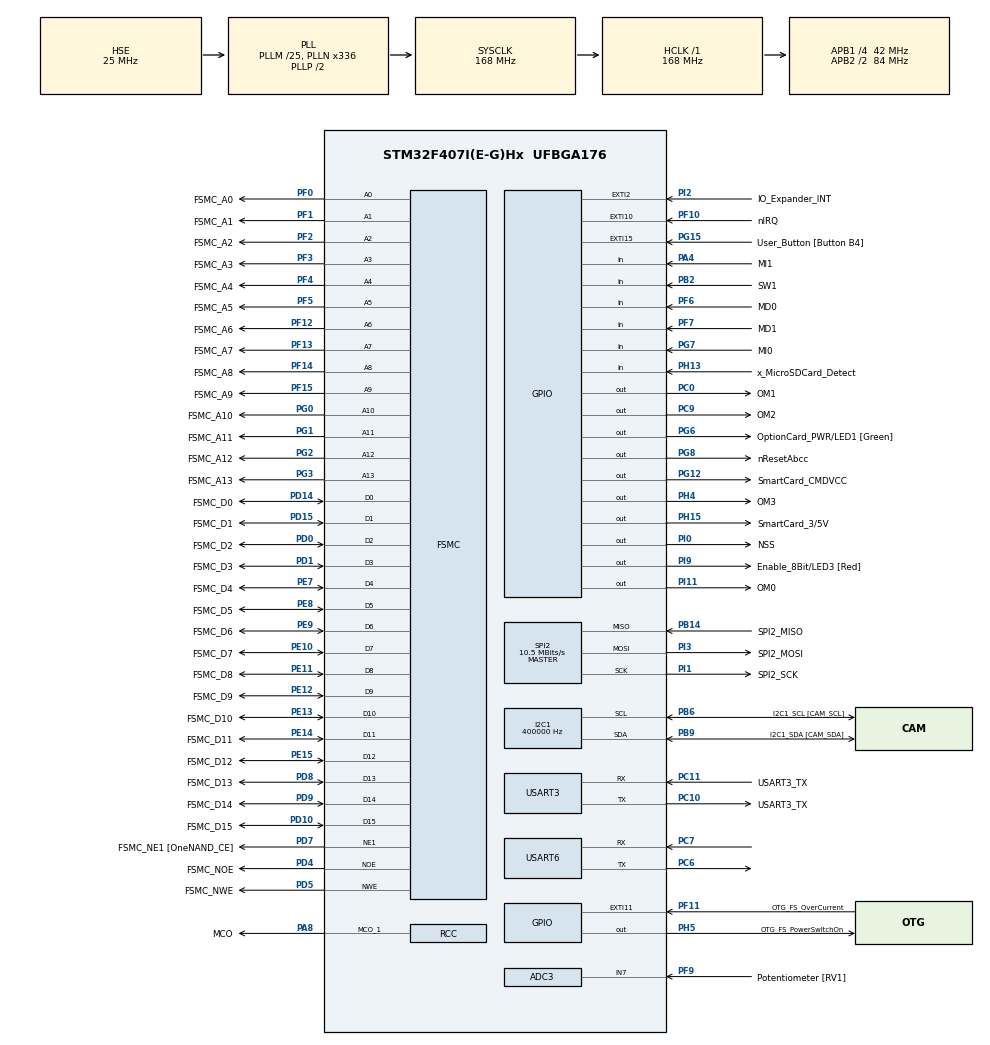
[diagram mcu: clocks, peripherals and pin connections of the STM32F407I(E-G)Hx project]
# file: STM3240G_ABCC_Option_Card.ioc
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ADC3.Channel-0\#ChannelRegularConversion=ADC_CHANNEL_7
ADC3.NbrOfConversionFlag=1
ADC3.Rank-0\#ChannelRegularConversion=1
ADC3.SamplingTime-0\#ChannelRegularConversion=ADC_SAMPLETIME_3CYCLES
Dma.Request0=SPI2_TX
Dma.Request1=SPI2_RX
Dma.SPI2_RX.1.Direction=DMA_PERIPH_TO_MEMORY
Dma.SPI2_RX.1.FIFOMode=DMA_FIFOMODE_DISABLE
Dma.SPI2_RX.1.Instance=DMA1_Stream3
Dma.SPI2_RX.1.MemDataAlignment=DMA_MDATAALIGN_BYTE
Dma.SPI2_RX.1.MemInc=DMA_MINC_ENABLE
Dma.SPI2_RX.1.Mode=DMA_NORMAL
Dma.SPI2_RX.1.PeriphDataAlignment=DMA_PDATAALIGN_BYTE
Dma.SPI2_RX.1.PeriphInc=DMA_PINC_DISABLE
Dma.SPI2_RX.1.Priority=DMA_PRIORITY_HIGH
Dma.SPI2_TX.0.Direction=DMA_MEMORY_TO_PERIPH
Dma.SPI2_TX.0.FIFOMode=DMA_FIFOMODE_DISABLE
Dma.SPI2_TX.0.Instance=DMA1_Stream4
Dma.SPI2_TX.0.MemDataAlignment=DMA_MDATAALIGN_BYTE
Dma.SPI2_TX.0.MemInc=DMA_MINC_ENABLE
Dma.SPI2_TX.0.Mode=DMA_NORMAL
Dma.SPI2_TX.0.PeriphDataAlignment=DMA_PDATAALIGN_BYTE
Dma.SPI2_TX.0.PeriphInc=DMA_PINC_DISABLE
Dma.SPI2_TX.0.Priority=DMA_PRIORITY_LOW
FSMC.AddressSetupTime1=0
FSMC.BusTurnAroundDuration1=6
FSMC.DataSetupTime1=30
I2C1.ClockSpeed=400000
I2C1.I2C_Mode=I2C_Fast
Mcu.Family=STM32F4
Mcu.Name=STM32F407I(E-G)Hx
Mcu.Package=UFBGA176
NVIC.DMA1_Stream3_IRQn=true\:0\:0\:false\:false\:true\:true
NVIC.DMA1_Stream4_IRQn=true\:0\:0\:false\:false\:true\:true
NVIC.EXTI15_10_IRQn=true\:0\:0\:false\:false\:true\:true
NVIC.PriorityGroup=NVIC_PRIORITYGROUP_0
NVIC.TIM5_IRQn=true\:0\:0\:false\:false\:true\:true
PA0-WKUP.GPIO_Label=WAKEUP [Button B2]
PA0-WKUP.Mode=SYS_WakeUp0
PA0-WKUP.Signal=SYS_WKUP
PA1.GPIO_Mode=GPIO_MODE_AF_PP
PA1.GPIO_PuPd=GPIO_NOPULL
PA1.GPIO_Speed=GPIO_SPEED_FREQ_LOW
PA1.Signal=ETH_RX_CLK
PA10.GPIO_Mode=GPIO_MODE_AF_PP
PA10.GPIO_PuPd=GPIO_NOPULL
PA10.GPIO_Speed=GPIO_SPEED_FREQ_LOW
PA10.Signal=USB_OTG_FS_ID
PA11.GPIO_Mode=GPIO_MODE_AF_PP
PA11.GPIO_PuPd=GPIO_NOPULL
PA11.GPIO_Speed=GPIO_SPEED_FREQ_LOW
PA11.Signal=USB_OTG_FS_DM
PA12.GPIO_Mode=GPIO_MODE_AF_PP
PA12.GPIO_PuPd=GPIO_NOPULL
PA12.GPIO_Speed=GPIO_SPEED_FREQ_LOW
PA12.Signal=USB_OTG_FS_DP
PA13.GPIO_Label=TMS/SWDIO
PA13.Mode=Trace_Asynchronous_SW
PA13.Signal=SYS_JTMS-SWDIO
PA14.GPIO_Label=TCK/SWCLK
PA14.Mode=Trace_Asynchronous_SW
PA14.Signal=SYS_JTCK-SWCLK
PA15.GPIO_Label=TDI
PA15.Signal=SYS_JTDI
PA2.GPIO_Mode=GPIO_MODE_AF_PP
PA2.GPIO_PuPd=GPIO_NOPULL
PA2.GPIO_Speed=GPIO_SPEED_FREQ_LOW
PA2.Signal=ETH_MDIO
PA3.GPIO_Mode=GPIO_MODE_AF_PP
PA3.GPIO_PuPd=GPIO_NOPULL
PA3.GPIO_Speed=GPIO_SPEED_FREQ_VERY_HIGH
PA3.Signal=USB_OTG_HS_ULPI_D0
PA4.GPIO_Label=MI1
PA4.GPIO_Mode=GPIO_MODE_INPUT
PA4.GPIO_PuPd=GPIO_NOPULL
PA4.Signal=GPIO_Input
PA5.GPIO_Mode=GPIO_MODE_AF_PP
PA5.GPIO_PuPd=GPIO_NOPULL
PA5.GPIO_Speed=GPIO_SPEED_FREQ_VERY_HIGH
PA5.Signal=USB_OTG_HS_ULPI_CK
PA6.GPIO_Mode=GPIO_MODE_AF_PP
PA6.GPIO_PuPd=GPIO_NOPULL
PA6.GPIO_Speed=GPIO_SPEED_FREQ_LOW
PA6.Signal=DCMI_PIXCK
PA7.GPIO_Mode=GPIO_MODE_AF_PP
PA7.GPIO_PuPd=GPIO_NOPULL
PA7.GPIO_Speed=GPIO_SPEED_FREQ_LOW
PA7.Signal=ETH_RX_DV
PA8.GPIO_Label=MCO
PA8.GPIO_Mode=GPIO_MODE_AF_PP
PA8.GPIO_PuPd=GPIO_NOPULL
PA8.GPIO_Speed=GPIO_SPEED_FREQ_LOW
PA8.Mode=Clock-out-1
PA8.Signal=RCC_MCO_1
PA9.GPIO_Mode=GPIO_MODE_INPUT
PA9.GPIO_PuPd=GPIO_NOPULL
PA9.Signal=USB_OTG_FS_VBUS
PB0.GPIO_Mode=GPIO_MODE_AF_PP
PB0.GPIO_PuPd=GPIO_NOPULL
PB0.GPIO_Speed=GPIO_SPEED_FREQ_VERY_HIGH
PB0.Signal=USB_OTG_HS_ULPI_D1
PB1.GPIO_Mode=GPIO_MODE_AF_PP
PB1.GPIO_PuPd=GPIO_NOPULL
PB1.GPIO_Speed=GPIO_SPEED_FREQ_VERY_HIGH
PB1.Signal=USB_OTG_HS_ULPI_D2
PB10.GPIO_Mode=GPIO_MODE_AF_PP
PB10.GPIO_PuPd=GPIO_NOPULL
PB10.GPIO_Speed=GPIO_SPEED_FREQ_VERY_HIGH
PB10.Signal=USB_OTG_HS_ULPI_D3
PB11.GPIO_Mode=GPIO_MODE_AF_PP
PB11.GPIO_PuPd=GPIO_NOPULL
PB11.GPIO_Speed=GPIO_SPEED_FREQ_VERY_HIGH
PB11.Signal=USB_OTG_HS_ULPI_D4
PB14.GPIO_Label=SPI2_MISO
PB14.Mode=Full_Duplex_Master
PB14.Signal=SPI2_MISO
PB2.GPIO_Label=SW1
PB2.GPIO_Mode=GPIO_MODE_INPUT
PB2.GPIO_PuPd=GPIO_NOPULL
PB2.Signal=GPIO_Input
PB3.GPIO_Label=TDO/SWO
PB3.Mode=Trace_Asynchronous_SW
PB3.Signal=SYS_JTDO-SWO
PB4.GPIO_Label=TRST
PB4.Signal=SYS_JTRST
PB5.GPIO_Mode=GPIO_MODE_AF_PP
PB5.GPIO_PuPd=GPIO_NOPULL
PB5.GPIO_Speed=GPIO_SPEED_FREQ_VERY_HIGH
PB5.Signal=USB_OTG_HS_ULPI_D7
PB6.GPIO_Label=I2C1_SCL [CAM_SCL]
PB6.GPIO_Mode=GPIO_MODE_AF_OD
PB6.GPIO_PuPd=GPIO_NOPULL
PB6.GPIO_PuPdOD=GPIO_PULLUP
PB6.GPIO_Speed=GPIO_SPEED_FREQ_LOW
PB6.Mode=I2C
PB6.Signal=I2C1_SCL
PB7.GPIO_Label=FSMC_NL [OneNAND_AVD]
PB7.GPIO_Mode=GPIO_MODE_AF_PP
PB7.GPIO_PuPd=GPIO_NOPULL
PB7.GPIO_Speed=GPIO_SPEED_FREQ_LOW
PB7.GPIO_Speed_High_Default=GPIO_SPEED_FREQ_VERY_HIGH
PB7.Signal=FSMC_NL
PB8.GPIO_Mode=GPIO_MODE_AF_PP
PB8.GPIO_PuPd=GPIO_NOPULL
PB8.GPIO_Speed=GPIO_SPEED_FREQ_LOW
PB8.Signal=ETH_TXD3
PB9.GPIO_Label=I2C1_SDA [CAM_SDA]
PB9.GPIO_Mode=GPIO_MODE_AF_OD
PB9.GPIO_PuPd=GPIO_NOPULL
PB9.GPIO_PuPdOD=GPIO_PULLUP
PB9.GPIO_Speed=GPIO_SPEED_FREQ_LOW
PB9.Mode=I2C
PB9.Signal=I2C1_SDA
PC0.GPIO_Label=OM1
PC0.GPIO_ModeDefaultOutputPP=GPIO_MODE_OUTPUT_PP
PC0.GPIO_PuPd=GPIO_PULLUP
PC0.GPIO_Speed=GPIO_SPEED_FREQ_LOW
PC0.Signal=GPIO_Output
PC1.GPIO_Mode=GPIO_MODE_AF_PP
PC1.GPIO_PuPd=GPIO_NOPULL
PC1.GPIO_Speed=GPIO_SPEED_FREQ_LOW
PC1.Signal=ETH_MDC
PC10.GPIO_Label=USART3_TX
PC10.GPIO_Mode=GPIO_MODE_AF_PP
PC10.GPIO_PuPd=GPIO_NOPULL
PC10.GPIO_Speed=GPIO_SPEED_FREQ_LOW
PC10.Mode=Asynchronous
PC10.Signal=USART3_TX
PC11.GPIO_Label=USART3_TX
PC11.GPIO_Mode=GPIO_MODE_AF_PP
PC11.GPIO_PuPd=GPIO_NOPULL
PC11.GPIO_Speed=GPIO_SPEED_FREQ_LOW
PC11.Mode=Asynchronous
PC11.Signal=USART3_RX
PC12.GPIO_Label=MicroSDCard_CLK
PC12.GPIO_Mode=GPIO_MODE_AF_PP
PC12.GPIO_PuPd=GPIO_NOPULL
PC12.GPIO_Speed=GPIO_SPEED_FREQ_LOW
PC12.GPIO_Speed_High_Default=GPIO_SPEED_FREQ_VERY_HIGH
PC12.Signal=SDIO_CK
PC13-ANTI_TAMP.GPIO_Label=Anti_Tamper [Button B3]
PC13-ANTI_TAMP.Signal=RTC_AF1
PC14-OSC32_IN.GPIO_Label=PC14-OSC32_IN
PC14-OSC32_IN.Signal=RCC_OSC32_IN
PC15-OSC32_OUT.GPIO_Label=PC15-OSC32_OUT
PC15-OSC32_OUT.Signal=RCC_OSC32_OUT
PC2.GPIO_Mode=GPIO_MODE_AF_PP
PC2.GPIO_PuPd=GPIO_NOPULL
PC2.GPIO_Speed=GPIO_SPEED_FREQ_LOW
PC2.Signal=ETH_TXD2
PC3.GPIO_Mode=GPIO_MODE_AF_PP
PC3.GPIO_PuPd=GPIO_NOPULL
PC3.GPIO_Speed=GPIO_SPEED_FREQ_LOW
PC3.Signal=ETH_TX_CLK
PC4.GPIO_Mode=GPIO_MODE_AF_PP
PC4.GPIO_PuPd=GPIO_NOPULL
PC4.GPIO_Speed=GPIO_SPEED_FREQ_LOW
PC4.Signal=ETH_RXD0
PC5.GPIO_Mode=GPIO_MODE_AF_PP
PC5.GPIO_PuPd=GPIO_NOPULL
PC5.GPIO_Speed=GPIO_SPEED_FREQ_LOW
PC5.Signal=ETH_RXD1
PC6.Mode=Asynchronous
PC6.Signal=USART6_TX
PC7.Mode=Asynchronous
PC7.Signal=USART6_RX
PC8.GPIO_Label=MicroSDCard_D0
PC8.GPIO_Mode=GPIO_MODE_AF_PP
PC8.GPIO_PuPd=GPIO_NOPULL
PC8.GPIO_Speed=GPIO_SPEED_FREQ_LOW
PC8.GPIO_Speed_High_Default=GPIO_SPEED_FREQ_VERY_HIGH
PC8.Signal=SDIO_D0
PC9.GPIO_Label=OM2
PC9.GPIO_ModeDefaultOutputPP=GPIO_MODE_OUTPUT_PP
PC9.GPIO_PuPd=GPIO_PULLUP
PC9.GPIO_Speed=GPIO_SPEED_FREQ_LOW
PC9.Signal=GPIO_Output
PD0.GPIO_Label=FSMC_D2
PD0.GPIO_Mode=GPIO_MODE_AF_PP
PD0.GPIO_PuPd=GPIO_NOPULL
PD0.GPIO_Speed=GPIO_SPEED_FREQ_LOW
PD0.GPIO_Speed_High_Default=GPIO_SPEED_FREQ_VERY_HIGH
PD0.Signal=FSMC_D2_DA2
PD1.GPIO_Label=FSMC_D3
PD1.GPIO_Mode=GPIO_MODE_AF_PP
PD1.GPIO_PuPd=GPIO_NOPULL
PD1.GPIO_Speed=GPIO_SPEED_FREQ_LOW
PD1.GPIO_Speed_High_Default=GPIO_SPEED_FREQ_VERY_HIGH
PD1.Signal=FSMC_D3_DA3
PD10.GPIO_Label=FSMC_D15
PD10.GPIO_Mode=GPIO_MODE_AF_PP
PD10.GPIO_PuPd=GPIO_NOPULL
PD10.GPIO_Speed=GPIO_SPEED_FREQ_LOW
PD10.GPIO_Speed_High_Default=GPIO_SPEED_FREQ_VERY_HIGH
PD10.Signal=FSMC_D15_DA15
PD11.GPIO_Mode=GPIO_MODE_AF_PP
PD11.GPIO_PuPd=GPIO_NOPULL
PD11.GPIO_Speed=GPIO_SPEED_FREQ_LOW
PD11.GPIO_Speed_High_Default=GPIO_SPEED_FREQ_VERY_HIGH
PD11.Signal=FSMC_A16_CLE
PD12.GPIO_Mode=GPIO_MODE_AF_PP
PD12.GPIO_PuPd=GPIO_NOPULL
PD12.GPIO_Speed=GPIO_SPEED_FREQ_LOW
PD12.GPIO_Speed_High_Default=GPIO_SPEED_FREQ_VERY_HIGH
PD12.Signal=FSMC_A17_ALE
PD13.GPIO_Mode=GPIO_MODE_AF_PP
PD13.GPIO_PuPd=GPIO_NOPULL
PD13.GPIO_Speed=GPIO_SPEED_FREQ_LOW
PD13.GPIO_Speed_High_Default=GPIO_SPEED_FREQ_VERY_HIGH
PD13.Signal=FSMC_A18
PD14.GPIO_Label=FSMC_D0
PD14.GPIO_Mode=GPIO_MODE_AF_PP
PD14.GPIO_PuPd=GPIO_NOPULL
PD14.GPIO_Speed=GPIO_SPEED_FREQ_LOW
PD14.GPIO_Speed_High_Default=GPIO_SPEED_FREQ_VERY_HIGH
PD14.Signal=FSMC_D0_DA0
PD15.GPIO_Label=FSMC_D1
PD15.GPIO_Mode=GPIO_MODE_AF_PP
PD15.GPIO_PuPd=GPIO_NOPULL
PD15.GPIO_Speed=GPIO_SPEED_FREQ_LOW
PD15.GPIO_Speed_High_Default=GPIO_SPEED_FREQ_VERY_HIGH
PD15.Signal=FSMC_D1_DA1
PD2.GPIO_Label=MicroSDCard_CMD
PD2.GPIO_Mode=GPIO_MODE_AF_PP
PD2.GPIO_PuPd=GPIO_NOPULL
PD2.GPIO_Speed=GPIO_SPEED_FREQ_LOW
PD2.GPIO_Speed_High_Default=GPIO_SPEED_FREQ_VERY_HIGH
PD2.Signal=SDIO_CMD
PD3.GPIO_Label=FSMC_CLK [OneNAND_CLK]
PD3.GPIO_Mode=GPIO_MODE_AF_PP
PD3.GPIO_PuPd=GPIO_NOPULL
PD3.GPIO_Speed=GPIO_SPEED_FREQ_LOW
PD3.GPIO_Speed_High_Default=GPIO_SPEED_FREQ_VERY_HIGH
PD3.Signal=FSMC_CLK
PD4.GPIO_Label=FSMC_NOE
PD4.GPIO_Mode=GPIO_MODE_AF_PP
PD4.GPIO_PuPd=GPIO_NOPULL
PD4.GPIO_Speed=GPIO_SPEED_FREQ_LOW
PD4.GPIO_Speed_High_Default=GPIO_SPEED_FREQ_VERY_HIGH
PD4.Signal=FSMC_NOE
PD5.GPIO_Label=FSMC_NWE
PD5.GPIO_Mode=GPIO_MODE_AF_PP
PD5.GPIO_PuPd=GPIO_NOPULL
PD5.GPIO_Speed=GPIO_SPEED_FREQ_LOW
PD5.GPIO_Speed_High_Default=GPIO_SPEED_FREQ_VERY_HIGH
PD5.Signal=FSMC_NWE
PD6.GPIO_Label=FSMC_NWAIT [OneNAND_RDY]
PD6.GPIO_Mode=GPIO_MODE_AF_PP
PD6.GPIO_PuPd=GPIO_NOPULL
PD6.GPIO_Speed=GPIO_SPEED_FREQ_LOW
PD6.GPIO_Speed_High_Default=GPIO_SPEED_FREQ_VERY_HIGH
PD6.Signal=FSMC_NWAIT
PD7.GPIO_Label=FSMC_NE1 [OneNAND_CE]
PD7.GPIO_Mode=GPIO_MODE_AF_PP
PD7.GPIO_PuPd=GPIO_NOPULL
PD7.GPIO_Speed=GPIO_SPEED_FREQ_LOW
PD7.GPIO_Speed_High_Default=GPIO_SPEED_FREQ_VERY_HIGH
PD7.Mode=NorPsramChipSelect1_1
PD7.Signal=FSMC_NE1
PD8.GPIO_Label=FSMC_D13
PD8.GPIO_Mode=GPIO_MODE_AF_PP
PD8.GPIO_PuPd=GPIO_NOPULL
PD8.GPIO_Speed=GPIO_SPEED_FREQ_LOW
PD8.GPIO_Speed_High_Default=GPIO_SPEED_FREQ_VERY_HIGH
PD8.Signal=FSMC_D13_DA13
PD9.GPIO_Label=FSMC_D14
PD9.GPIO_Mode=GPIO_MODE_AF_PP
PD9.GPIO_PuPd=GPIO_NOPULL
PD9.GPIO_Speed=GPIO_SPEED_FREQ_LOW
PD9.GPIO_Speed_High_Default=GPIO_SPEED_FREQ_VERY_HIGH
PD9.Signal=FSMC_D14_DA14
PE0.GPIO_Label=FSMC_NBL0 [SRAM_BLE]
PE0.GPIO_Mode=GPIO_MODE_AF_PP
PE0.GPIO_PuPd=GPIO_NOPULL
PE0.GPIO_Speed=GPIO_SPEED_FREQ_LOW
PE0.GPIO_Speed_High_Default=GPIO_SPEED_FREQ_VERY_HIGH
PE0.Signal=FSMC_NBL0
PE1.GPIO_Label=FSMC_NBL1 [SRAM_BHE]
PE1.GPIO_Mode=GPIO_MODE_AF_PP
PE1.GPIO_PuPd=GPIO_NOPULL
PE1.GPIO_Speed=GPIO_SPEED_FREQ_LOW
PE1.GPIO_Speed_High_Default=GPIO_SPEED_FREQ_VERY_HIGH
PE1.Signal=FSMC_NBL1
PE10.GPIO_Label=FSMC_D7
PE10.GPIO_Mode=GPIO_MODE_AF_PP
PE10.GPIO_PuPd=GPIO_NOPULL
PE10.GPIO_Speed=GPIO_SPEED_FREQ_LOW
PE10.GPIO_Speed_High_Default=GPIO_SPEED_FREQ_VERY_HIGH
PE10.Signal=FSMC_D7_DA7
PE11.GPIO_Label=FSMC_D8
PE11.GPIO_Mode=GPIO_MODE_AF_PP
PE11.GPIO_PuPd=GPIO_NOPULL
PE11.GPIO_Speed=GPIO_SPEED_FREQ_LOW
PE11.GPIO_Speed_High_Default=GPIO_SPEED_FREQ_VERY_HIGH
PE11.Signal=FSMC_D8_DA8
PE12.GPIO_Label=FSMC_D9
PE12.GPIO_Mode=GPIO_MODE_AF_PP
PE12.GPIO_PuPd=GPIO_NOPULL
PE12.GPIO_Speed=GPIO_SPEED_FREQ_LOW
PE12.GPIO_Speed_High_Default=GPIO_SPEED_FREQ_VERY_HIGH
PE12.Signal=FSMC_D9_DA9
PE13.GPIO_Label=FSMC_D10
PE13.GPIO_Mode=GPIO_MODE_AF_PP
PE13.GPIO_PuPd=GPIO_NOPULL
PE13.GPIO_Speed=GPIO_SPEED_FREQ_LOW
PE13.GPIO_Speed_High_Default=GPIO_SPEED_FREQ_VERY_HIGH
PE13.Signal=FSMC_D10_DA10
PE14.GPIO_Label=FSMC_D11
PE14.GPIO_Mode=GPIO_MODE_AF_PP
PE14.GPIO_PuPd=GPIO_NOPULL
PE14.GPIO_Speed=GPIO_SPEED_FREQ_LOW
PE14.GPIO_Speed_High_Default=GPIO_SPEED_FREQ_VERY_HIGH
PE14.Signal=FSMC_D11_DA11
PE15.GPIO_Label=FSMC_D12
PE15.GPIO_Mode=GPIO_MODE_AF_PP
PE15.GPIO_PuPd=GPIO_NOPULL
PE15.GPIO_Speed=GPIO_SPEED_FREQ_LOW
PE15.GPIO_Speed_High_Default=GPIO_SPEED_FREQ_VERY_HIGH
PE15.Signal=FSMC_D12_DA12
PE2.GPIO_Label=TRACE_CLK
PE2.GPIO_Mode=GPIO_MODE_AF_PP
PE2.GPIO_PuPd=GPIO_NOPULL
PE2.GPIO_Speed=GPIO_SPEED_FREQ_LOW
PE2.Signal=SYS_TRACECLK
PE3.GPIO_Mode=GPIO_MODE_AF_PP
PE3.GPIO_PuPd=GPIO_NOPULL
PE3.GPIO_Speed=GPIO_SPEED_FREQ_LOW
PE3.GPIO_Speed_High_Default=GPIO_SPEED_FREQ_VERY_HIGH
PE3.Signal=FSMC_A19
PE4.GPIO_Mode=GPIO_MODE_AF_PP
PE4.GPIO_PuPd=GPIO_NOPULL
PE4.GPIO_Speed=GPIO_SPEED_FREQ_LOW
PE4.GPIO_Speed_High_Default=GPIO_SPEED_FREQ_VERY_HIGH
PE4.Signal=FSMC_A20
PE5.GPIO_Label=TRACE_D2
PE5.GPIO_Mode=GPIO_MODE_AF_PP
PE5.GPIO_PuPd=GPIO_NOPULL
PE5.GPIO_Speed=GPIO_SPEED_FREQ_LOW
PE5.Signal=SYS_TRACED2
PE6.GPIO_Label=TRACE_D3
PE6.GPIO_Mode=GPIO_MODE_AF_PP
PE6.GPIO_PuPd=GPIO_NOPULL
PE6.GPIO_Speed=GPIO_SPEED_FREQ_LOW
PE6.Signal=SYS_TRACED3
PE7.GPIO_Label=FSMC_D4
PE7.GPIO_Mode=GPIO_MODE_AF_PP
PE7.GPIO_PuPd=GPIO_NOPULL
PE7.GPIO_Speed=GPIO_SPEED_FREQ_LOW
PE7.GPIO_Speed_High_Default=GPIO_SPEED_FREQ_VERY_HIGH
PE7.Signal=FSMC_D4_DA4
PE8.GPIO_Label=FSMC_D5
PE8.GPIO_Mode=GPIO_MODE_AF_PP
PE8.GPIO_PuPd=GPIO_NOPULL
PE8.GPIO_Speed=GPIO_SPEED_FREQ_LOW
PE8.GPIO_Speed_High_Default=GPIO_SPEED_FREQ_VERY_HIGH
PE8.Signal=FSMC_D5_DA5
PE9.GPIO_Label=FSMC_D6
PE9.GPIO_Mode=GPIO_MODE_AF_PP
PE9.GPIO_PuPd=GPIO_NOPULL
PE9.GPIO_Speed=GPIO_SPEED_FREQ_LOW
PE9.GPIO_Speed_High_Default=GPIO_SPEED_FREQ_VERY_HIGH
PE9.Signal=FSMC_D6_DA6
PF0.GPIO_Label=FSMC_A0
PF0.GPIO_Mode=GPIO_MODE_AF_PP
PF0.GPIO_PuPd=GPIO_NOPULL
PF0.GPIO_Speed=GPIO_SPEED_FREQ_LOW
PF0.GPIO_Speed_High_Default=GPIO_SPEED_FREQ_VERY_HIGH
PF0.Signal=FSMC_A0
PF1.GPIO_Label=FSMC_A1
PF1.GPIO_Mode=GPIO_MODE_AF_PP
PF1.GPIO_PuPd=GPIO_NOPULL
PF1.GPIO_Speed=GPIO_SPEED_FREQ_LOW
PF1.GPIO_Speed_High_Default=GPIO_SPEED_FREQ_VERY_HIGH
PF1.Signal=FSMC_A1
PF10.GPIO_Label=nIRQ
PF10.GPIO_ModeDefaultEXTI=GPIO_MODE_IT_FALLING
PF10.GPIO_PuPd=GPIO_PULLUP
PF10.Signal=GPXTI10
PF11.GPIO_Label=OTG_FS_OverCurrent
PF11.GPIO_ModeDefaultEXTI=GPIO_MODE_EVT_RISING
PF11.GPIO_PuPd=GPIO_NOPULL
PF11.Signal=GPXTI11
PF12.GPIO_Label=FSMC_A6
PF12.GPIO_Mode=GPIO_MODE_AF_PP
PF12.GPIO_PuPd=GPIO_NOPULL
PF12.GPIO_Speed=GPIO_SPEED_FREQ_LOW
PF12.GPIO_Speed_High_Default=GPIO_SPEED_FREQ_VERY_HIGH
PF12.Signal=FSMC_A6
PF13.GPIO_Label=FSMC_A7
PF13.GPIO_Mode=GPIO_MODE_AF_PP
PF13.GPIO_PuPd=GPIO_NOPULL
PF13.GPIO_Speed=GPIO_SPEED_FREQ_LOW
PF13.GPIO_Speed_High_Default=GPIO_SPEED_FREQ_VERY_HIGH
PF13.Signal=FSMC_A7
PF14.GPIO_Label=FSMC_A8
PF14.GPIO_Mode=GPIO_MODE_AF_PP
PF14.GPIO_PuPd=GPIO_NOPULL
PF14.GPIO_Speed=GPIO_SPEED_FREQ_LOW
PF14.GPIO_Speed_High_Default=GPIO_SPEED_FREQ_VERY_HIGH
PF14.Signal=FSMC_A8
PF15.GPIO_Label=FSMC_A9
PF15.GPIO_Mode=GPIO_MODE_AF_PP
PF15.GPIO_PuPd=GPIO_NOPULL
PF15.GPIO_Speed=GPIO_SPEED_FREQ_LOW
PF15.GPIO_Speed_High_Default=GPIO_SPEED_FREQ_VERY_HIGH
PF15.Signal=FSMC_A9
PF2.GPIO_Label=FSMC_A2
PF2.GPIO_Mode=GPIO_MODE_AF_PP
PF2.GPIO_PuPd=GPIO_NOPULL
PF2.GPIO_Speed=GPIO_SPEED_FREQ_LOW
PF2.GPIO_Speed_High_Default=GPIO_SPEED_FREQ_VERY_HIGH
PF2.Signal=FSMC_A2
PF3.GPIO_Label=FSMC_A3
PF3.GPIO_Mode=GPIO_MODE_AF_PP
PF3.GPIO_PuPd=GPIO_NOPULL
PF3.GPIO_Speed=GPIO_SPEED_FREQ_LOW
PF3.GPIO_Speed_High_Default=GPIO_SPEED_FREQ_VERY_HIGH
PF3.Signal=FSMC_A3
PF4.GPIO_Label=FSMC_A4
PF4.GPIO_Mode=GPIO_MODE_AF_PP
PF4.GPIO_PuPd=GPIO_NOPULL
PF4.GPIO_Speed=GPIO_SPEED_FREQ_LOW
PF4.GPIO_Speed_High_Default=GPIO_SPEED_FREQ_VERY_HIGH
PF4.Signal=FSMC_A4
PF5.GPIO_Label=FSMC_A5
PF5.GPIO_Mode=GPIO_MODE_AF_PP
PF5.GPIO_PuPd=GPIO_NOPULL
PF5.GPIO_Speed=GPIO_SPEED_FREQ_LOW
PF5.GPIO_Speed_High_Default=GPIO_SPEED_FREQ_VERY_HIGH
PF5.Signal=FSMC_A5
PF6.GPIO_Label=MD0
PF6.GPIO_Mode=GPIO_MODE_INPUT
PF6.GPIO_PuPd=GPIO_NOPULL
PF6.Signal=GPIO_Input
PF7.GPIO_Label=MD1
PF7.GPIO_Mode=GPIO_MODE_INPUT
PF7.GPIO_PuPd=GPIO_NOPULL
PF7.Signal=GPIO_Input
PF9.GPIO_Label=Potentiometer [RV1]
PF9.GPIO_Mode=GPIO_MODE_ANALOG
PF9.GPIO_PuPd=GPIO_NOPULL
PF9.Mode=IN7
PF9.Signal=ADC3_IN7
PG0.GPIO_Label=FSMC_A10
PG0.GPIO_Mode=GPIO_MODE_AF_PP
PG0.GPIO_PuPd=GPIO_NOPULL
PG0.GPIO_Speed=GPIO_SPEED_FREQ_LOW
PG0.GPIO_Speed_High_Default=GPIO_SPEED_FREQ_VERY_HIGH
PG0.Signal=FSMC_A10
PG1.GPIO_Label=FSMC_A11
PG1.GPIO_Mode=GPIO_MODE_AF_PP
PG1.GPIO_PuPd=GPIO_NOPULL
PG1.GPIO_Speed=GPIO_SPEED_FREQ_LOW
PG1.GPIO_Speed_High_Default=GPIO_SPEED_FREQ_VERY_HIGH
PG1.Signal=FSMC_A11
PG10.GPIO_Label=FSMC_NE3 [TFT-LCD_CS]
PG10.GPIO_Mode=GPIO_MODE_AF_PP
PG10.GPIO_PuPd=GPIO_NOPULL
PG10.GPIO_Speed=GPIO_SPEED_FREQ_LOW
PG10.GPIO_Speed_High_Default=GPIO_SPEED_FREQ_VERY_HIGH
PG10.Signal=FSMC_NE3
PG11.GPIO_Mode=GPIO_MODE_AF_PP
PG11.GPIO_PuPd=GPIO_NOPULL
PG11.GPIO_Speed=GPIO_SPEED_FREQ_LOW
PG11.Signal=ETH_TX_EN
PG12.GPIO_Label=SmartCard_CMDVCC
PG12.GPIO_Mode=GPIO_MODE_OUTPUT_PP
PG12.GPIO_ModeDefaultOutputPP=GPIO_MODE_OUTPUT_PP
PG12.GPIO_PuPd=GPIO_NOPULL
PG12.GPIO_Speed=GPIO_SPEED_FREQ_LOW
PG12.Signal=GPIO_Output
PG13.GPIO_Mode=GPIO_MODE_AF_PP
PG13.GPIO_PuPd=GPIO_NOPULL
PG13.GPIO_Speed=GPIO_SPEED_FREQ_LOW
PG13.Signal=ETH_TXD0
PG14.GPIO_Mode=GPIO_MODE_AF_PP
PG14.GPIO_PuPd=GPIO_NOPULL
PG14.GPIO_Speed=GPIO_SPEED_FREQ_LOW
PG14.Signal=ETH_TXD1
PG15.GPIO_Label=User_Button [Button B4]
PG15.GPIO_ModeDefaultEXTI=GPIO_MODE_EVT_RISING
PG15.GPIO_PuPd=GPIO_NOPULL
PG15.Signal=GPXTI15
PG2.GPIO_Label=FSMC_A12
PG2.GPIO_Mode=GPIO_MODE_AF_PP
PG2.GPIO_PuPd=GPIO_NOPULL
PG2.GPIO_Speed=GPIO_SPEED_FREQ_LOW
PG2.GPIO_Speed_High_Default=GPIO_SPEED_FREQ_VERY_HIGH
PG2.Signal=FSMC_A12
PG3.GPIO_Label=FSMC_A13
PG3.GPIO_Mode=GPIO_MODE_AF_PP
PG3.GPIO_PuPd=GPIO_NOPULL
PG3.GPIO_Speed=GPIO_SPEED_FREQ_LOW
PG3.GPIO_Speed_High_Default=GPIO_SPEED_FREQ_VERY_HIGH
PG3.Signal=FSMC_A13
PG4.GPIO_Mode=GPIO_MODE_AF_PP
PG4.GPIO_PuPd=GPIO_NOPULL
PG4.GPIO_Speed=GPIO_SPEED_FREQ_LOW
PG4.GPIO_Speed_High_Default=GPIO_SPEED_FREQ_VERY_HIGH
PG4.Signal=FSMC_A14
PG5.GPIO_Mode=GPIO_MODE_AF_PP
PG5.GPIO_PuPd=GPIO_NOPULL
PG5.GPIO_Speed=GPIO_SPEED_FREQ_LOW
PG5.GPIO_Speed_High_Default=GPIO_SPEED_FREQ_VERY_HIGH
PG5.Signal=FSMC_A15
PG6.GPIO_Label=OptionCard_PWR/LED1 [Green]
PG6.GPIO_Mode=GPIO_MODE_OUTPUT_PP
PG6.GPIO_ModeDefaultOutputPP=GPIO_MODE_OUTPUT_PP
PG6.GPIO_PuPd=GPIO_NOPULL
PG6.GPIO_Speed=GPIO_SPEED_FREQ_LOW
PG6.PinState=GPIO_PIN_SET
PG6.Signal=GPIO_Output
PG7.GPIO_Label=MI0
PG7.GPIO_Mode=GPIO_MODE_INPUT
PG7.GPIO_PuPd=GPIO_NOPULL
PG7.Signal=GPIO_Input
PG8.GPIO_Label=nResetAbcc
PG8.GPIO_ModeDefaultOutputPP=GPIO_MODE_OUTPUT_PP
PG8.GPIO_PuPd=GPIO_PULLUP
PG8.GPIO_Speed=GPIO_SPEED_FREQ_VERY_HIGH
PG8.Signal=GPIO_Output
PG9.GPIO_Label=FSMC_NE2 [SDRAM_CE]
PG9.GPIO_Mode=GPIO_MODE_AF_PP
PG9.GPIO_PuPd=GPIO_NOPULL
PG9.GPIO_Speed=GPIO_SPEED_FREQ_LOW
PG9.GPIO_Speed_High_Default=GPIO_SPEED_FREQ_VERY_HIGH
PG9.Signal=FSMC_NE2
PH0-OSC_IN.GPIO_Label=PH0-OSC_IN
PH0-OSC_IN.Mode=HSE-External-Oscillator
PH0-OSC_IN.Signal=RCC_OSC_IN
PH1-OSC_OUT.GPIO_Label=PH1-OSC_OUT
PH1-OSC_OUT.Mode=HSE-External-Oscillator
PH1-OSC_OUT.Signal=RCC_OSC_OUT
PH10.GPIO_Mode=GPIO_MODE_AF_PP
PH10.GPIO_PuPd=GPIO_NOPULL
PH10.GPIO_Speed=GPIO_SPEED_FREQ_LOW
PH10.Signal=DCMI_D1
PH11.GPIO_Mode=GPIO_MODE_AF_PP
PH11.GPIO_PuPd=GPIO_NOPULL
PH11.GPIO_Speed=GPIO_SPEED_FREQ_LOW
PH11.Signal=DCMI_D2
PH12.GPIO_Mode=GPIO_MODE_AF_PP
PH12.GPIO_PuPd=GPIO_NOPULL
PH12.GPIO_Speed=GPIO_SPEED_FREQ_LOW
PH12.Signal=DCMI_D3
PH13.GPIO_Label=x_MicroSDCard_Detect
PH13.GPIO_Mode=GPIO_MODE_INPUT
PH13.GPIO_PuPd=GPIO_PULLUP
PH13.Signal=GPIO_Input
PH14.GPIO_Mode=GPIO_MODE_AF_PP
PH14.GPIO_PuPd=GPIO_NOPULL
PH14.GPIO_Speed=GPIO_SPEED_FREQ_LOW
PH14.Signal=DCMI_D4
PH15.GPIO_Label=SmartCard_3/5V
PH15.GPIO_Mode=GPIO_MODE_OUTPUT_PP
PH15.GPIO_ModeDefaultOutputPP=GPIO_MODE_OUTPUT_PP
PH15.GPIO_PuPd=GPIO_NOPULL
PH15.GPIO_Speed=GPIO_SPEED_FREQ_LOW
PH15.Signal=GPIO_Output
PH3.GPIO_Mode=GPIO_MODE_AF_PP
PH3.GPIO_PuPd=GPIO_NOPULL
PH3.GPIO_Speed=GPIO_SPEED_FREQ_LOW
PH3.Signal=ETH_COL
PH4.GPIO_Label=OM3
PH4.Signal=GPIO_Output
PH5.GPIO_Label=OTG_FS_PowerSwitchOn
PH5.GPIO_Mode=GPIO_MODE_OUTPUT_PP
PH5.GPIO_ModeDefaultOutputPP=GPIO_MODE_OUTPUT_PP
PH5.GPIO_PuPd=GPIO_NOPULL
PH5.GPIO_Speed=GPIO_SPEED_FREQ_LOW
PH5.Signal=GPIO_Output
PH6.GPIO_Mode=GPIO_MODE_AF_PP
PH6.GPIO_PuPd=GPIO_NOPULL
PH6.GPIO_Speed=GPIO_SPEED_FREQ_LOW
PH6.Signal=ETH_RXD2
PH7.GPIO_Mode=GPIO_MODE_AF_PP
PH7.GPIO_PuPd=GPIO_NOPULL
PH7.GPIO_Speed=GPIO_SPEED_FREQ_LOW
PH7.Signal=ETH_RXD3
PH8.GPIO_Mode=GPIO_MODE_AF_PP
PH8.GPIO_PuPd=GPIO_NOPULL
PH8.GPIO_Speed=GPIO_SPEED_FREQ_LOW
PH8.Signal=DCMI_HSYNC
PH9.GPIO_Mode=GPIO_MODE_AF_PP
PH9.GPIO_PuPd=GPIO_NOPULL
PH9.GPIO_Speed=GPIO_SPEED_FREQ_LOW
PH9.Signal=DCMI_D0
PI0.GPIO_Label=NSS
PI0.GPIO_ModeDefaultOutputPP=GPIO_MODE_OUTPUT_PP
PI0.GPIO_PuPd=GPIO_PULLUP
PI0.GPIO_Speed=GPIO_SPEED_FREQ_HIGH
PI0.Signal=GPIO_Output
PI1.GPIO_Label=SPI2_SCK
PI1.Mode=Full_Duplex_Master
PI1.Signal=SPI2_SCK
PI10.GPIO_Mode=GPIO_MODE_AF_PP
PI10.GPIO_PuPd=GPIO_NOPULL
PI10.GPIO_Speed=GPIO_SPEED_FREQ_LOW
PI10.Signal=ETH_RX_ER
PI11.GPIO_Label=OM0
PI11.GPIO_ModeDefaultOutputPP=GPIO_MODE_OUTPUT_PP
PI11.GPIO_PuPd=GPIO_PULLUP
PI11.GPIO_Speed=GPIO_SPEED_FREQ_LOW
PI11.Signal=GPIO_Output
PI2.GPIO_Label=IO_Expander_INT
PI2.GPIO_ModeDefaultEXTI=GPIO_MODE_EVT_RISING
PI2.GPIO_PuPd=GPIO_NOPULL
PI2.Signal=GPXTI2
PI3.GPIO_Label=SPI2_MOSI
PI3.Mode=Full_Duplex_Master
PI3.Signal=SPI2_MOSI
PI4.GPIO_Mode=GPIO_MODE_AF_PP
PI4.GPIO_PuPd=GPIO_NOPULL
PI4.GPIO_Speed=GPIO_SPEED_FREQ_LOW
PI4.Signal=DCMI_D5
PI5.GPIO_Mode=GPIO_MODE_AF_PP
PI5.GPIO_PuPd=GPIO_NOPULL
PI5.GPIO_Speed=GPIO_SPEED_FREQ_LOW
PI5.Signal=DCMI_VSYNC
PI6.GPIO_Mode=GPIO_MODE_AF_PP
PI6.GPIO_PuPd=GPIO_NOPULL
PI6.GPIO_Speed=GPIO_SPEED_FREQ_LOW
PI6.Signal=DCMI_D6
PI7.GPIO_Mode=GPIO_MODE_AF_PP
PI7.GPIO_PuPd=GPIO_NOPULL
PI7.GPIO_Speed=GPIO_SPEED_FREQ_LOW
PI7.Signal=DCMI_D7
PI9.GPIO_Label=Enable_8Bit/LED3 [Red]
PI9.GPIO_Mode=GPIO_MODE_OUTPUT_PP
PI9.GPIO_ModeDefaultOutputPP=GPIO_MODE_OUTPUT_PP
PI9.GPIO_PuPd=GPIO_NOPULL
PI9.GPIO_Speed=GPIO_SPEED_FREQ_LOW
PI9.Signal=GPIO_Output
ProjectManager.HeapSize=0x400
ProjectManager.StackSize=0x200
ProjectManager.TargetToolchain=MDK-ARM V5
RCC.48MHZClocksFreq_Value=48000000
RCC.AHBFreq_Value=168000000
RCC.APB1CLKDivider=RCC_HCLK_DIV4
RCC.APB1Freq_Value=42000000
RCC.APB1TimFreq_Value=84000000
RCC.APB2CLKDivider=RCC_HCLK_DIV2
RCC.APB2Freq_Value=84000000
RCC.APB2TimFreq_Value=168000000
RCC.CortexFreq_Value=168000000
RCC.FLatency-AdvancedSettings=FLASH_LATENCY_5
RCC.HCLKFreq_Value=168000000
RCC.HSE_VALUE=25000000
RCC.HSI_VALUE=16000000
RCC.LSE_VALUE=32768
RCC.PLLM=25
RCC.PLLN=336
RCC.PLLQ=7
RCC.PLLSourceVirtual=RCC_PLLSOURCE_HSE
RCC.PWR_Regulator_Voltage_Scale-AdvancedSettings=PWR_REGULATOR_VOLTAGE_SCALE1
RCC.SYSCLKFreq_VALUE=168000000
RCC.SYSCLKSource=RCC_SYSCLKSOURCE_PLLCLK
RCC.VCOOutputFreq_Value=336000000
SH.FSMC_A0.0=FSMC_A0,14b-a1
SH.FSMC_A1.0=FSMC_A1,14b-a1
SH.FSMC_A10.0=FSMC_A10,14b-a1
SH.FSMC_A11.0=FSMC_A11,14b-a1
SH.FSMC_A12.0=FSMC_A12,14b-a1
SH.FSMC_A13.0=FSMC_A13,14b-a1
SH.FSMC_A14.0=FSMC_A14
SH.FSMC_A15.0=FSMC_A15
SH.FSMC_A16_CLE.0=FSMC_A16
SH.FSMC_A17_ALE.0=FSMC_A17
SH.FSMC_A18.0=FSMC_A18
SH.FSMC_A19.0=FSMC_A19
SH.FSMC_A2.0=FSMC_A2,14b-a1
SH.FSMC_A20.0=FSMC_A20
SH.FSMC_A3.0=FSMC_A3,14b-a1
SH.FSMC_A4.0=FSMC_A4,14b-a1
SH.FSMC_A5.0=FSMC_A5,14b-a1
SH.FSMC_A6.0=FSMC_A6,14b-a1
SH.FSMC_A7.0=FSMC_A7,14b-a1
SH.FSMC_A8.0=FSMC_A8,14b-a1
SH.FSMC_A9.0=FSMC_A9,14b-a1
SH.FSMC_CLK.0=FSMC_CLK
SH.FSMC_D0_DA0.0=FSMC_D0,16b-d1
SH.FSMC_D10_DA10.0=FSMC_D10,16b-d1
SH.FSMC_D11_DA11.0=FSMC_D11,16b-d1
SH.FSMC_D12_DA12.0=FSMC_D12,16b-d1
SH.FSMC_D13_DA13.0=FSMC_D13,16b-d1
SH.FSMC_D14_DA14.0=FSMC_D14,16b-d1
SH.FSMC_D15_DA15.0=FSMC_D15,16b-d1
SH.FSMC_D1_DA1.0=FSMC_D1,16b-d1
SH.FSMC_D2_DA2.0=FSMC_D2,16b-d1
SH.FSMC_D3_DA3.0=FSMC_D3,16b-d1
SH.FSMC_D4_DA4.0=FSMC_D4,16b-d1
SH.FSMC_D5_DA5.0=FSMC_D5,16b-d1
SH.FSMC_D6_DA6.0=FSMC_D6,16b-d1
SH.FSMC_D7_DA7.0=FSMC_D7,16b-d1
SH.FSMC_D8_DA8.0=FSMC_D8,16b-d1
SH.FSMC_D9_DA9.0=FSMC_D9,16b-d1
SH.FSMC_NBL0.0=FSMC_NBL0
SH.FSMC_NBL1.0=FSMC_NBL1
SH.FSMC_NL.0=FSMC_NL
SH.FSMC_NOE.0=FSMC_NOE,Sram1
SH.FSMC_NWAIT.0=FSMC_NWAIT
SH.FSMC_NWE.0=FSMC_NWE,Sram1
SPI2.BaudRatePrescaler=SPI_BAUDRATEPRESCALER_4
SPI2.CLKPhase=SPI_PHASE_2EDGE
SPI2.CLKPolarity=SPI_POLARITY_HIGH
SPI2.CalculateBaudRate=10.5 MBits/s
SPI2.Direction=SPI_DIRECTION_2LINES
SPI2.Mode=SPI_MODE_MASTER
SPI2.VirtualType=VM_MASTER
TIM5.Period=0xFFFFFFFF
TIM5.Prescaler=83
USART3.VirtualMode=VM_ASYNC
USART6.VirtualMode=VM_ASYNC
VP_TIM5_VS_ClockSourceINT.Mode=Internal
board=STM3240G-EVAL

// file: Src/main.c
/*******************************************************************************
********************************************************************************
**                                                                            **
** ABCC Starter Kit version 3.08.01 (2021-12-15)                              **
**                                                                            **
** Delivered with:                                                            **
**    ABP            7.79.01 (2021-11-10)                                     **
**    ABCC Driver    5.08.01 (2021-12-09)                                     **
**                                                                            */

/**
  ******************************************************************************
  * @file           : main.c
  * @brief          : Main program body
  ******************************************************************************
  ** This notice applies to any and all portions of this file
  * that are not between comment pairs USER CODE BEGIN and
  * USER CODE END. Other portions of this file, whether
  * inserted by the user or by software development tools
  * are owned by their respective copyright owners.
  *
  * COPYRIGHT(c) 2018 STMicroelectronics
  *
  * Redistribution and use in source and binary forms, with or without modification,
  * are permitted provided that the following conditions are met:
  *   1. Redistributions of source code must retain the above copyright notice,
  *      this list of conditions and the following disclaimer.
  *   2. Redistributions in binary form must reproduce the above copyright notice,
  *      this list of conditions and the following disclaimer in the documentation
  *      and/or other materials provided with the distribution.
  *   3. Neither the name of STMicroelectronics nor the names of its contributors
  *      may be used to endorse or promote products derived from this software
  *      without specific prior written permission.
  *
  * THIS SOFTWARE IS PROVIDED BY THE COPYRIGHT HOLDERS AND CONTRIBUTORS "AS IS"
  * AND ANY EXPRESS OR IMPLIED WARRANTIES, INCLUDING, BUT NOT LIMITED TO, THE
  * IMPLIED WARRANTIES OF MERCHANTABILITY AND FITNESS FOR A PARTICULAR PURPOSE ARE
  * DISCLAIMED. IN NO EVENT SHALL THE COPYRIGHT HOLDER OR CONTRIBUTORS BE LIABLE
  * FOR ANY DIRECT, INDIRECT, INCIDENTAL, SPECIAL, EXEMPLARY, OR CONSEQUENTIAL
  * DAMAGES (INCLUDING, BUT NOT LIMITED TO, PROCUREMENT OF SUBSTITUTE GOODS OR
  * SERVICES; LOSS OF USE, DATA, OR PROFITS; OR BUSINESS INTERRUPTION) HOWEVER
  * CAUSED AND ON ANY THEORY OF LIABILITY, WHETHER IN CONTRACT, STRICT LIABILITY,
  * OR TORT (INCLUDING NEGLIGENCE OR OTHERWISE) ARISING IN ANY WAY OUT OF THE USE
  * OF THIS SOFTWARE, EVEN IF ADVISED OF THE POSSIBILITY OF SUCH DAMAGE.
  *
  ******************************************************************************
  */
#include "main.h"
#include "stm32f4xx_hal.h"
#include "adc.h"
#include "dma.h"
#include "i2c.h"
#include "spi.h"
#include "tim.h"
#include "usart.h"
#include "gpio.h"
#include "fsmc.h"

/* USER CODE BEGIN Includes */
#include "abcc_td.h"
#include "abcc.h"
#include "abcc_sys_adapt.h"
#include "ad_obj.h"
#include "appl_abcc_handler.h"
#include "Serial.h"
#ifdef __USE_LCD
#include "GLCD.h"
#endif
#include "abcc_versions.h"
#include "appl_adi_config.h"

/* USER CODE END Includes */

/* USER CODE BEGIN PV */
/* Private variables ---------------------------------------------------------*/

/* ABCC defines */
#define APPL_TIMER_MS         1
#define USE_TIMER_INTERRUPT   1

/* USER CODE END PV */

void SystemClock_Config(void);

/* USER CODE BEGIN PFP */
/* Private function prototypes -----------------------------------------------*/

/* USER CODE END PFP */

/* USER CODE BEGIN 0 */
#if ( APPL_ACTIVE_ADI_SETUP == APPL_ADI_SETUP_BOARD_SPECIFIC )
void DemoInit( void )
{
   UINT8 abData[2] = {0xFF, 0x00};
   #ifdef __USE_LCD
   UINT8 bOpMode;
   #endif

   /* Link UART3 to STDIO and print a basic message */
   SER_LinkStdio(&huart3);
   printf("HMS Industrial Networks\n\r");
   printf("Embedded ABCC Demo\n\r");
   printf("STM3240G-EVAL with ABCC Option Card\n\r");
   printf( ABCC_STARTER_KIT_VER_STRING );
   printf("\n\r\n\r");

   #ifdef __USE_LCD
   /* Initialize the staticly displayed region of the LCD */
   GLCD_Init();
   GLCD_Clear(White);
   GLCD_SetBackColor(Blue);
   GLCD_SetTextColor(White);
   GLCD_DisplayString(0, 0, 1, (unsigned char *)"    HMS Networks    ");
   GLCD_DisplayString(1, 0, 1, (unsigned char *)" Embedded ABCC Demo ");
   GLCD_DisplayString(2, 0, 1, (unsigned char *)"  hms-networks.com  ");
   GLCD_SetTextColor(White);
   GLCD_SetBackColor(Black);
   GLCD_ClearLn (9, 0);
   GLCD_ClearLn (10, 0);
   bOpMode = ABCC_GetOpmode();
   if( bOpMode == ABP_OP_MODE_16_BIT_PARALLEL )
   {
      GLCD_DisplayString(10, 0, 0, (unsigned char *)"16-BIT PARALLEL MODE");
   }
   else if( bOpMode == ABP_OP_MODE_8_BIT_PARALLEL )
   {
      GLCD_DisplayString(10, 0, 0, (unsigned char *)"8-BIT PARALLEL MODE");
   }
   else if( bOpMode == ABP_OP_MODE_SPI )
   {
      GLCD_DisplayString(10, 0, 0, (unsigned char *)"SPI MODE");
   }
   else if ( ( bOpMode == ABP_OP_MODE_SERIAL_19_2 )  ||
             ( bOpMode == ABP_OP_MODE_SERIAL_57_6 )  ||
             ( bOpMode == ABP_OP_MODE_SERIAL_115_2 ) ||
             ( bOpMode == ABP_OP_MODE_SERIAL_625 ) )
   {
      GLCD_DisplayString(10, 0, 0, (unsigned char *)"SERIAL MODE");
   }
   GLCD_DisplayString(9, 0, 0, (unsigned char *)ABCC_STARTER_KIT_VER_STRING );
   GLCD_SetBackColor(White);
   GLCD_SetTextColor(Blue);
   GLCD_DisplayString(4, 0, 1, (unsigned char *)"Pot Val:");
   GLCD_DisplayString(5, 0, 1, (unsigned char *)"Key State  :");
   GLCD_DisplayString(6, 0, 1, (unsigned char *)"4-LED State:");
   GLCD_DisplayString(7, 0, 1, (unsigned char *)"8-LED State:");
   GLCD_DisplayString(8, 0, 1, (unsigned char *)"8-I/O State:");
   GLCD_DisplayString(9, 0, 1, (unsigned char *)"TIM Cnt:");
   GLCD_SetTextColor(Red);
   GLCD_DisplayString(5, 13, 1, (unsigned char *)"FALSE");
   GLCD_DisplayString(6, 13, 1, (unsigned char *)"0x0");
   GLCD_DisplayString(7, 13, 1, (unsigned char *)"0x00");
   GLCD_DisplayString(8, 13, 1, (unsigned char *)"0x00");
   GLCD_DisplayString(9, 9,  1, (unsigned char *)"0x00000000");
   #endif
   /* Reset the I2C I/O-Expanders to default 'off' state */
   HAL_I2C_Master_Transmit(&hi2c1, 0x44 , abData, 2, 1000);
   abData[0] = 0xFF;
   abData[1] = 0xFF;
   HAL_I2C_Master_Transmit(&hi2c1, 0x40 , abData, 2, 1000);

}
#endif /* ( APPL_ACTIVE_ADI_SETUP == APPL_ADI_SETUP_BOARD_SPECIFIC ) */

/* USER CODE END 0 */

int main(void)
{
  /* USER CODE BEGIN 1 */
   /*
   ** Make sure the ABCC reset signal is kept low by the platform specific
   ** initialization to keep the ABCC module in reset until the driver releases
   ** it.
   */
   APPL_AbccHandlerStatusType eAbccHandlerStatus = APPL_MODULE_NO_ERROR;

  /* USER CODE END 1 */

  /* MCU Configuration----------------------------------------------------------*/

  /* Reset of all peripherals, Initializes the Flash interface and the Systick. */
  HAL_Init();

  /* Configure the system clock */
  SystemClock_Config();

  /* Initialize all configured peripherals */
  MX_GPIO_Init();
  MX_DMA_Init();
  MX_ADC3_Init();
  MX_FSMC_Init();
  MX_I2C1_Init();
  MX_SPI2_Init();
  MX_TIM5_Init();
  MX_USART3_UART_Init();
  MX_USART6_UART_Init();
  /* USER CODE BEGIN 2 */
  if( ABCC_HwInit() != ABCC_EC_NO_ERROR )
  {
     Error_Handler();
  }

#if ( APPL_ACTIVE_ADI_SETUP == APPL_ADI_SETUP_BOARD_SPECIFIC )
   DemoInit();
#endif /* ( APPL_ACTIVE_ADI_SETUP == APPL_ADI_SETUP_BOARD_SPECIFIC ) */

  /* USER CODE END 2 */

  /* Infinite loop */
  /* USER CODE BEGIN WHILE */
   while(eAbccHandlerStatus == APPL_MODULE_NO_ERROR )
   {
      eAbccHandlerStatus = APPL_HandleAbcc();

#if( !USE_TIMER_INTERRUPT )
      ABCC_RunTimerSystem( APPL_TIMER_MS );
      HAL_Delay( APPL_TIMER_MS );
#endif
      switch( eAbccHandlerStatus )
      {
      case APPL_MODULE_NO_ERROR:
         break;
      case APPL_MODULE_RESET:
         HAL_NVIC_SystemReset();
         break;
      case APPL_MODULE_NOT_DETECTED:
      case APPL_MODULE_NOT_SUPPORTED:
      case APPL_MODULE_NOT_ANSWERING:
      case APPL_MODULE_SHUTDOWN:
      case APPL_MODULE_UNEXPECTED_ERROR:
      default:
         printf( "\nAPPL_HandleAbcc() returned status code: %d\n", eAbccHandlerStatus );
         break;
      }
  /* USER CODE END WHILE */

  /* USER CODE BEGIN 3 */
   }

   #ifdef __USE_LCD
   GLCD_Clear(Black);
   GLCD_SetBackColor(Red);
   GLCD_SetTextColor(White);
   GLCD_DisplayString(5, 0, 1, (unsigned char *)" APPLICATION HALTED ");
   #endif

   printf("Application HALTED!\n\n");
  /* USER CODE END 3 */

}

void SystemClock_Config(void)
{

  RCC_OscInitTypeDef RCC_OscInitStruct;
  RCC_ClkInitTypeDef RCC_ClkInitStruct;

    /**Configure the main internal regulator output voltage
    */
  __HAL_RCC_PWR_CLK_ENABLE();

  __HAL_PWR_VOLTAGESCALING_CONFIG(PWR_REGULATOR_VOLTAGE_SCALE1);

    /**Initializes the CPU, AHB and APB busses clocks
    */
  RCC_OscInitStruct.OscillatorType = RCC_OSCILLATORTYPE_HSI|RCC_OSCILLATORTYPE_HSE;
  RCC_OscInitStruct.HSEState = RCC_HSE_ON;
  RCC_OscInitStruct.HSIState = RCC_HSI_ON;
  RCC_OscInitStruct.HSICalibrationValue = 16;
  RCC_OscInitStruct.PLL.PLLState = RCC_PLL_ON;
  RCC_OscInitStruct.PLL.PLLSource = RCC_PLLSOURCE_HSE;
  RCC_OscInitStruct.PLL.PLLM = 25;
  RCC_OscInitStruct.PLL.PLLN = 336;
  RCC_OscInitStruct.PLL.PLLP = RCC_PLLP_DIV2;
  RCC_OscInitStruct.PLL.PLLQ = 7;
  if (HAL_RCC_OscConfig(&RCC_OscInitStruct) != HAL_OK)
  {
    _Error_Handler(__FILE__, __LINE__);
  }

    /**Initializes the CPU, AHB and APB busses clocks
    */
  RCC_ClkInitStruct.ClockType = RCC_CLOCKTYPE_HCLK|RCC_CLOCKTYPE_SYSCLK
                              |RCC_CLOCKTYPE_PCLK1|RCC_CLOCKTYPE_PCLK2;
  RCC_ClkInitStruct.SYSCLKSource = RCC_SYSCLKSOURCE_PLLCLK;
  RCC_ClkInitStruct.AHBCLKDivider = RCC_SYSCLK_DIV1;
  RCC_ClkInitStruct.APB1CLKDivider = RCC_HCLK_DIV4;
  RCC_ClkInitStruct.APB2CLKDivider = RCC_HCLK_DIV2;

  if (HAL_RCC_ClockConfig(&RCC_ClkInitStruct, FLASH_LATENCY_5) != HAL_OK)
  {
    _Error_Handler(__FILE__, __LINE__);
  }

  HAL_RCC_MCOConfig(RCC_MCO1, RCC_MCO1SOURCE_HSI, RCC_MCODIV_1);

    /**Configure the Systick interrupt time
    */
  HAL_SYSTICK_Config(HAL_RCC_GetHCLKFreq()/1000);

    /**Configure the Systick
    */
  HAL_SYSTICK_CLKSourceConfig(SYSTICK_CLKSOURCE_HCLK);

  /* SysTick_IRQn interrupt configuration */
  HAL_NVIC_SetPriority(SysTick_IRQn, 0, 0);
}

/* USER CODE BEGIN 4 */

void HAL_SYSTICK_Callback(void)
{
   /* call timer functions */
   #if( USE_TIMER_INTERRUPT )
   ABCC_RunTimerSystem( APPL_TIMER_MS );
   #endif
}

/* USER CODE END 4 */

void _Error_Handler(char *file, int line)
{
  while(1)
  {
  }
}

/************************ (C) COPYRIGHT STMicroelectronics *****END OF FILE****/
